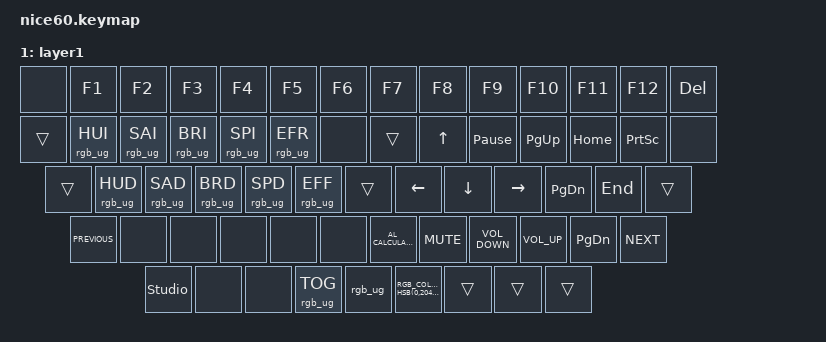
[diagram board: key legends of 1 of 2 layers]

  /*
  * Copyright (c) 2020 The ZMK Contributors
  *
  * SPDX-License-Identifier: MIT
  */

	#include <behaviors.dtsi>
	#include <dt-bindings/zmk/keys.h>
	#include <dt-bindings/zmk/rgb.h>
	#include <dt-bindings/zmk/bt.h>
	#include <dt-bindings/zmk/outputs.h>
	#include <dt-bindings/zmk/reset.h>
	#include <dt-bindings/zmk/ext_power.h>

  / {
    keymap {
      compatible = "zmk,keymap";
  layer0 {
          bindings = <
          &gresc &kp N1 &kp N2 &kp N3 &kp N4 &kp N5 &kp N6 &kp N7 &kp N8 &kp N9 &kp N0 &kp MINUS &kp EQUAL &kp BACKSPACE &kp TAB &kp Q &kp W &kp E &kp R &kp T &kp Y &kp U &kp I &kp O &kp P &kp LEFT_BRACKET &kp RIGHT_BRACKET &kp BACKSLASH &kp CAPSLOCK &kp A &kp S &kp D &kp F &kp G &kp H &kp J &kp K &kp L &kp SEMICOLON &kp SINGLE_QUOTE &kp ENTER &kp LEFT_SHIFT &kp Z &kp X &kp C &kp V &kp B &kp N &kp M &kp COMMA &kp DOT &kp SLASH &kp RIGHT_SHIFT &kp LEFT_CONTROL &kp LEFT_GUI &kp LEFT_ALT &kp SPACE &kp RIGHT_ALT &kp LEFT_GUI &mo 1 &kp RIGHT_CONTROL
          >;
        };
		layer1 {
          bindings = <
          &none &kp F1 &kp F2 &kp F3 &kp F4 &kp F5 &kp F6 &kp F7 &kp F8 &kp F9 &kp F10 &kp F11 &kp F12 &kp DELETE 
		  &trans &rgb_ug RGB_HUI  &rgb_ug RGB_SAI &rgb_ug RGB_BRI &rgb_ug RGB_SPI &rgb_ug RGB_EFR &none &trans &kp UP &kp PAUSE_BREAK &kp PAGE_UP &kp HOME &kp PRINTSCREEN &none 
		  &trans &rgb_ug RGB_HUD &rgb_ug RGB_SAD &rgb_ug RGB_BRD &rgb_ug RGB_SPD &rgb_ug RGB_EFF &trans &kp LEFT &kp DOWN &kp RIGHT &kp PAGE_DOWN &kp END &trans 
		  &kp C_PREVIOUS &none &none &none &none &none &kp C_AL_CALCULATOR &kp C_MUTE &kp C_VOLUME_DOWN &kp C_VOLUME_UP &kp PAGE_DOWN &kp C_NEXT 
		  &studio_unlock &none &none &rgb_ug RGB_TOG &rgb_ug RGB_COLOR_HSB(0,204,204) &trans &trans &trans
          >;
        };
    };
  };
  
